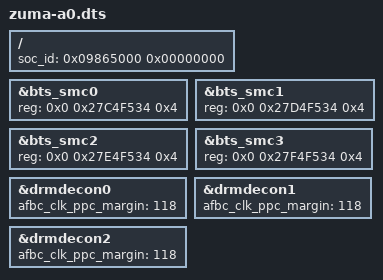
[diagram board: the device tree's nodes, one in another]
// SPDX-License-Identifier: GPL-2.0-only
/*
 * Copyright 2021 Google LLC.
 *
 */

/dts-v1/;
/ {
	/* soc revision info */
	soc_id = <0x09865000 0x00000000>;
};

#include "zuma.dtsi"
#include "zuma-sysmmu.dtsi"

&bts_smc0 {
	reg = <0x0 0x27C4F534 0x4>;
};

&bts_smc1 {
	reg = <0x0 0x27D4F534 0x4>;
};

&bts_smc2 {
	reg = <0x0 0x27E4F534 0x4>;
};

&bts_smc3 {
	reg = <0x0 0x27F4F534 0x4>;
};

&drmdecon0 {
	afbc_clk_ppc_margin = <118>; /* additional 18% margin for afbc layer clock */
};

&drmdecon1 {
	afbc_clk_ppc_margin = <118>; /* additional 18% margin for afbc layer clock */
};

&drmdecon2 {
	afbc_clk_ppc_margin = <118>; /* additional 18% margin for afbc layer clock */
};
